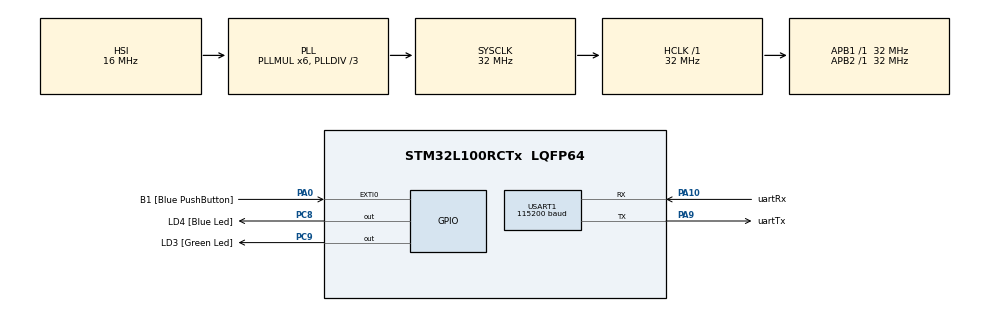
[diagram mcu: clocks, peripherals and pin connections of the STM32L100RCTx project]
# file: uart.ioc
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Mcu.Family=STM32L1
Mcu.Name=STM32L100RCTx
Mcu.Package=LQFP64
NVIC.PriorityGroup=NVIC_PRIORITYGROUP_0
PA0-WKUP1.GPIO_Label=B1 [Blue PushButton]
PA0-WKUP1.GPIO_ModeDefaultEXTI=GPIO_MODE_EVT_RISING
PA0-WKUP1.Signal=GPXTI0
PA10.GPIO_Label=uartRx
PA10.Mode=Asynchronous
PA10.Signal=USART1_RX
PA13.GPIO_Label=SWDIO
PA13.Mode=Serial_Wire
PA13.Signal=SYS_JTMS-SWDIO
PA14.GPIO_Label=SWCLK
PA14.Mode=Serial_Wire
PA14.Signal=SYS_JTCK-SWCLK
PA9.GPIO_Label=uartTx
PA9.Mode=Asynchronous
PA9.Signal=USART1_TX
PB3.GPIO_Label=SWO
PB3.Signal=SYS_JTDO-TRACESWO
PC14-OSC32_IN.GPIO_Label=PC14-OSC32_IN
PC14-OSC32_IN.Signal=RCC_OSC32_IN
PC15-OSC32_OUT.GPIO_Label=PC15-OSC32_OUT
PC15-OSC32_OUT.Signal=RCC_OSC32_OUT
PC8.GPIO_Label=LD4 [Blue Led]
PC8.Signal=GPIO_Output
PC9.GPIO_Label=LD3 [Green Led]
PC9.Signal=GPIO_Output
PH0-OSC_IN.GPIO_Label=PH0-OSC_IN
PH0-OSC_IN.Mode=HSE-External-Clock-Source
PH0-OSC_IN.Signal=RCC_OSC_IN
PH1-OSC_OUT.GPIO_Label=PH1-OSC_OUT
PH1-OSC_OUT.Signal=RCC_OSC_OUT
ProjectManager.HeapSize=0x200
ProjectManager.StackSize=0x400
ProjectManager.TargetToolchain=STM32CubeIDE
RCC.48MHZClocksFreq_Value=48000000
RCC.AHBFreq_Value=32000000
RCC.APB1Freq_Value=32000000
RCC.APB1TimFreq_Value=32000000
RCC.APB2Freq_Value=32000000
RCC.APB2TimFreq_Value=32000000
RCC.HCLKFreq_Value=32000000
RCC.HSE_VALUE=8000000
RCC.HSI_VALUE=16000000
RCC.LSEState=RCC_LSE_ON
RCC.LSE_VALUE=32768
RCC.MSI_VALUE=2097000
RCC.PLLDIV=RCC_PLL_DIV3
RCC.PLLMUL=RCC_PLL_MUL6
RCC.RTCClockSelectionVirtual=RCC_RTCCLKSOURCE_LSE
RCC.SYSCLKFreq_VALUE=32000000
RCC.SYSCLKSource=RCC_SYSCLKSOURCE_PLLCLK
RCC.USBOutput=48000000
RCC.VCOOutputFreq_Value=96000000
USART1.BaudRate=115200
USART1.VirtualMode=VM_ASYNC
board=STM32L100C-DISCO

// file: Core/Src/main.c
/* USER CODE BEGIN Header */
/**
  ******************************************************************************
  * @file           : main.c
  * @brief          : Main program body
  ******************************************************************************
  * @attention
  *
  * <h2><center>&copy; Copyright (c) 2020 STMicroelectronics.
  * All rights reserved.</center></h2>
  *
  * This software component is licensed by ST under BSD 3-Clause license,
  * the "License"; You may not use this file except in compliance with the
  * License. You may obtain a copy of the License at:
  *                        opensource.org/licenses/BSD-3-Clause
  *
  ******************************************************************************
  */
/* USER CODE END Header */

#include "main.h"

/* USER CODE BEGIN PM */
#define UART_STR "test\n"
/* USER CODE END PM */

UART_HandleTypeDef huart1;

void SystemClock_Config(void);
static void MX_GPIO_Init(void);
static void MX_USART1_UART_Init(void);

int main(void)
{

  /* MCU Configuration--------------------------------------------------------*/

  /* Reset of all peripherals, Initializes the Flash interface and the Systick. */
  HAL_Init();

  /* Configure the system clock */
  SystemClock_Config();

  /* Initialize all configured peripherals */
  MX_GPIO_Init();
  MX_USART1_UART_Init();

  /* Infinite loop */
  while (1)
  {

    /* USER CODE BEGIN 3 */
	  HAL_UART_Transmit(&huart1, UART_STR, sizeof(UART_STR), 100);
	  HAL_Delay(1000);
  }
  /* USER CODE END 3 */
}

void SystemClock_Config(void)
{
  RCC_OscInitTypeDef RCC_OscInitStruct = {0};
  RCC_ClkInitTypeDef RCC_ClkInitStruct = {0};

  /** Configure the main internal regulator output voltage
  */
  __HAL_PWR_VOLTAGESCALING_CONFIG(PWR_REGULATOR_VOLTAGE_SCALE1);
  /** Initializes the CPU, AHB and APB busses clocks
  */
  RCC_OscInitStruct.OscillatorType = RCC_OSCILLATORTYPE_HSI;
  RCC_OscInitStruct.HSIState = RCC_HSI_ON;
  RCC_OscInitStruct.HSICalibrationValue = RCC_HSICALIBRATION_DEFAULT;
  RCC_OscInitStruct.PLL.PLLState = RCC_PLL_ON;
  RCC_OscInitStruct.PLL.PLLSource = RCC_PLLSOURCE_HSI;
  RCC_OscInitStruct.PLL.PLLMUL = RCC_PLL_MUL6;
  RCC_OscInitStruct.PLL.PLLDIV = RCC_PLL_DIV3;
  if (HAL_RCC_OscConfig(&RCC_OscInitStruct) != HAL_OK)
  {
    Error_Handler();
  }
  /** Initializes the CPU, AHB and APB busses clocks
  */
  RCC_ClkInitStruct.ClockType = RCC_CLOCKTYPE_HCLK|RCC_CLOCKTYPE_SYSCLK
                              |RCC_CLOCKTYPE_PCLK1|RCC_CLOCKTYPE_PCLK2;
  RCC_ClkInitStruct.SYSCLKSource = RCC_SYSCLKSOURCE_PLLCLK;
  RCC_ClkInitStruct.AHBCLKDivider = RCC_SYSCLK_DIV1;
  RCC_ClkInitStruct.APB1CLKDivider = RCC_HCLK_DIV1;
  RCC_ClkInitStruct.APB2CLKDivider = RCC_HCLK_DIV1;

  if (HAL_RCC_ClockConfig(&RCC_ClkInitStruct, FLASH_LATENCY_1) != HAL_OK)
  {
    Error_Handler();
  }
}

static void MX_USART1_UART_Init(void)
{

  huart1.Instance = USART1;
  huart1.Init.BaudRate = 115200;
  huart1.Init.WordLength = UART_WORDLENGTH_8B;
  huart1.Init.StopBits = UART_STOPBITS_1;
  huart1.Init.Parity = UART_PARITY_NONE;
  huart1.Init.Mode = UART_MODE_TX_RX;
  huart1.Init.HwFlowCtl = UART_HWCONTROL_NONE;
  huart1.Init.OverSampling = UART_OVERSAMPLING_16;
  if (HAL_UART_Init(&huart1) != HAL_OK)
  {
    Error_Handler();
  }

}

static void MX_GPIO_Init(void)
{
  GPIO_InitTypeDef GPIO_InitStruct = {0};

  /* GPIO Ports Clock Enable */
  __HAL_RCC_GPIOC_CLK_ENABLE();
  __HAL_RCC_GPIOH_CLK_ENABLE();
  __HAL_RCC_GPIOA_CLK_ENABLE();
  __HAL_RCC_GPIOB_CLK_ENABLE();

  /*Configure GPIO pin Output Level */
  HAL_GPIO_WritePin(GPIOC, LD4_Pin|LD3_Pin, GPIO_PIN_RESET);

  /*Configure GPIO pin : B1_Pin */
  GPIO_InitStruct.Pin = B1_Pin;
  GPIO_InitStruct.Mode = GPIO_MODE_EVT_RISING;
  GPIO_InitStruct.Pull = GPIO_NOPULL;
  HAL_GPIO_Init(B1_GPIO_Port, &GPIO_InitStruct);

  /*Configure GPIO pins : LD4_Pin LD3_Pin */
  GPIO_InitStruct.Pin = LD4_Pin|LD3_Pin;
  GPIO_InitStruct.Mode = GPIO_MODE_OUTPUT_PP;
  GPIO_InitStruct.Pull = GPIO_NOPULL;
  GPIO_InitStruct.Speed = GPIO_SPEED_FREQ_LOW;
  HAL_GPIO_Init(GPIOC, &GPIO_InitStruct);

}

void Error_Handler(void)
{
  /* USER CODE BEGIN Error_Handler_Debug */
  /* User can add his own implementation to report the HAL error return state */
	while(1);
  /* USER CODE END Error_Handler_Debug */
}

/************************ (C) COPYRIGHT STMicroelectronics *****END OF FILE****/
